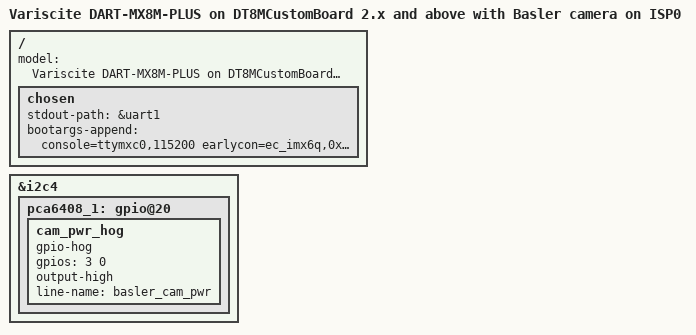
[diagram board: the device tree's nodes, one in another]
// SPDX-License-Identifier: (GPL-2.0+ OR MIT)
/*
 * Copyright 2019 NXP
 * Copyright 2020-2021 Variscite Ltd.
 */

#include "imx8mp-var-dart-dt8mcustomboard.dts"
#include "imx8mp-var-dart-dt8mcustomboard-basler-isp0.dtsi"

/ {
	model = "Variscite DART-MX8M-PLUS on DT8MCustomBoard 2.x and above with Basler camera on ISP0";
	chosen {
		stdout-path = &uart1;
		bootargs-append = "console=ttymxc0,115200 earlycon=ec_imx6q,0x30860000,115200 androidboot.console=ttymxc0 androidboot.primary_display=imx-drm androidboot.wifisdio=30b40000.mmc androidboot.btmmchost=mmc0 androidboot.camera.layout=basler";
	};
};

&i2c4 {
	pca6408_1: gpio@20 {
		cam_pwr_hog {
			gpio-hog;
			gpios = <3 0>;
			output-high;
			line-name = "basler_cam_pwr";
		};
	};
};
